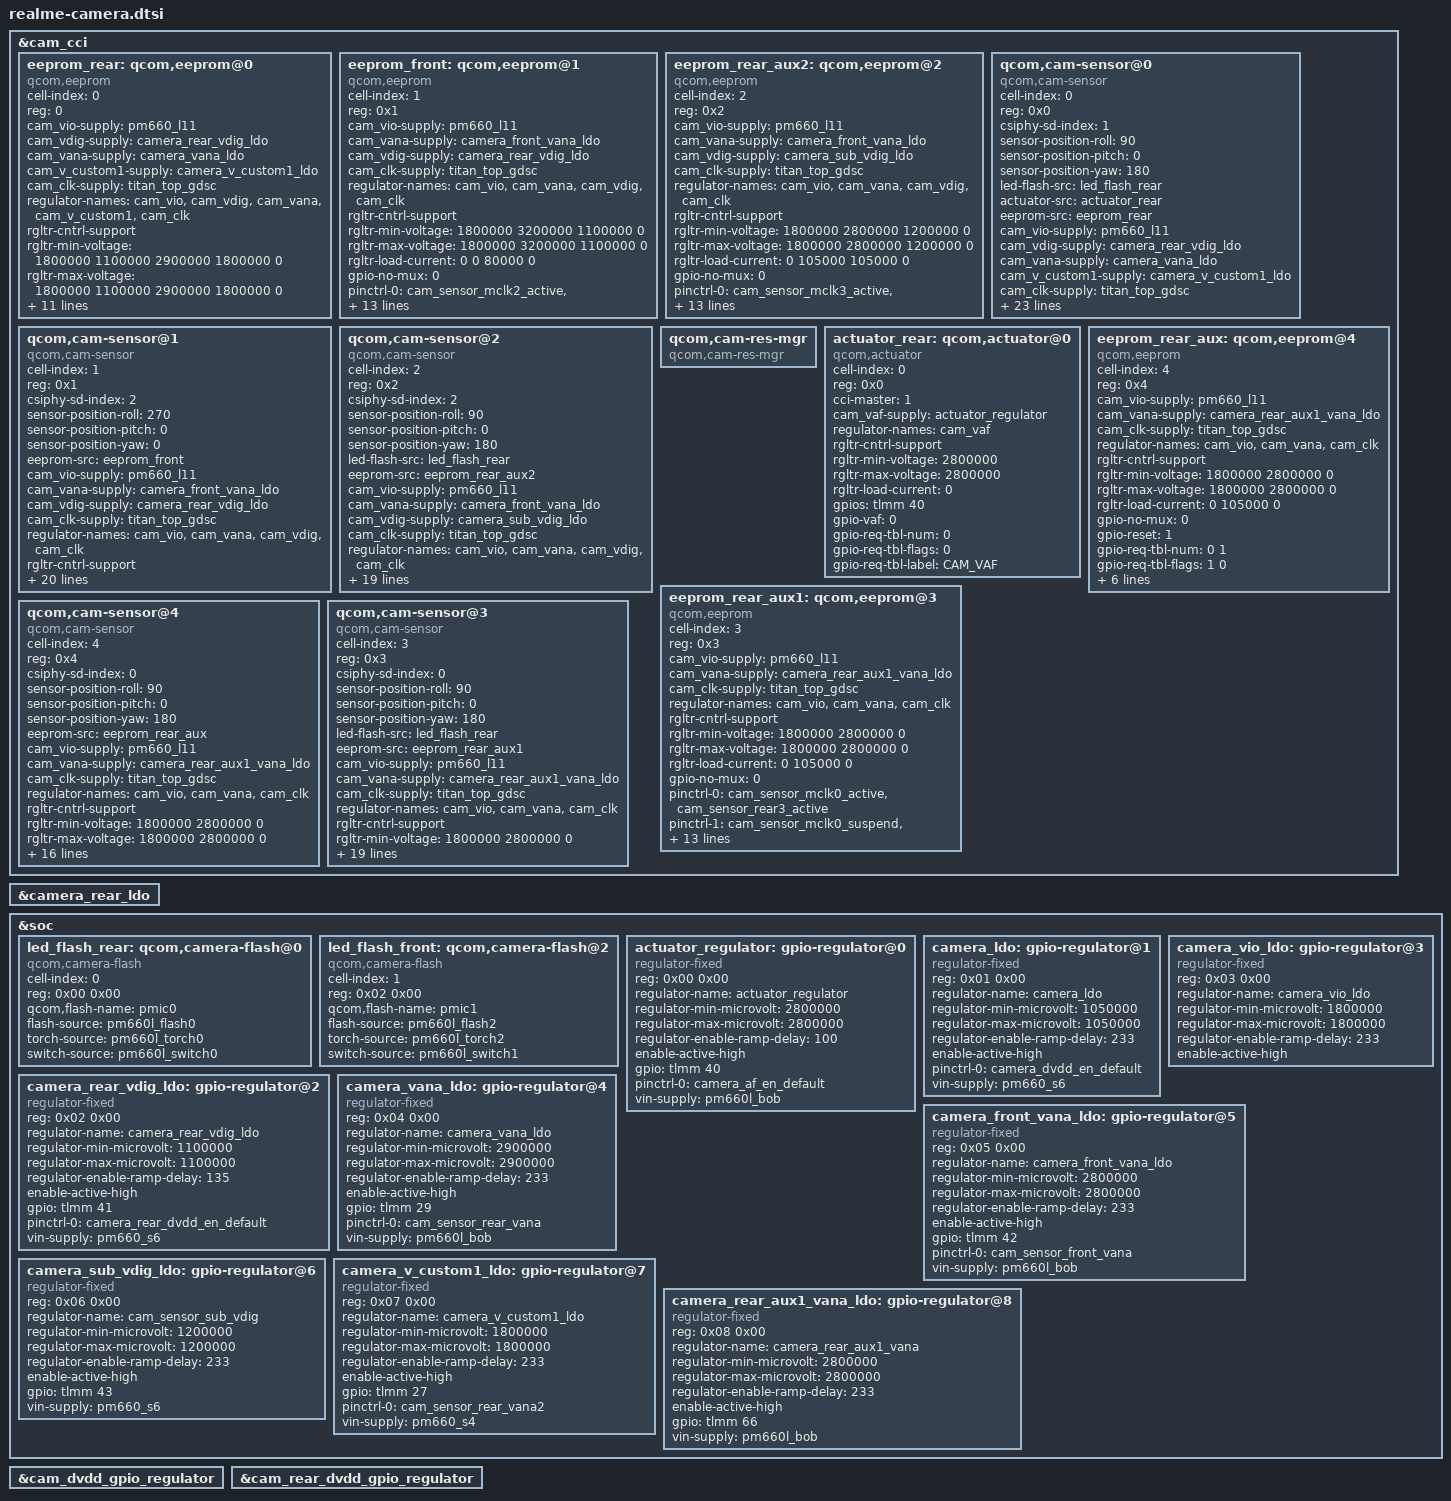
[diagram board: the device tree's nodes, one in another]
// SPDX-License-Identifier: GPL-2.0
// Copyright (c) 2021, Divyanshu-Modi <divyan.m05@gmail.com>
// Copyright (c) 2021, Dakkshesh07 <dakkshesh5@gmail.com>
// Copyright (c) 2021, The Linux Foundation. All rights reserved.

/* RMX 1921 specific changes */

&camera_vio_ldo {
	/delete-property/ gpio;
	/delete-property/ pinctrl-names;
	/delete-property/ pinctrl-0;
	/delete-property/ vin-supply;
};

&cam_cci {
	qcom,eeprom@0 {
                /delete-property/ pinctrl-names;
                /delete-property/ pinctrl-0;
                /delete-property/ pinctrl-1;
                /delete-property/ gpios;
        };

        qcom,eeprom@1 {
                /delete-property/ pinctrl-names;
                /delete-property/ pinctrl-0;
                /delete-property/ pinctrl-1;
                /delete-property/ gpios;
        };

        qcom,eeprom@2 {
                /delete-property/ pinctrl-names;
                /delete-property/ pinctrl-0;
                /delete-property/ pinctrl-1;
                /delete-property/ gpios;
        };

	qcom,cam-sensor@0 {
                /delete-property/ pinctrl-names;
                /delete-property/ pinctrl-0;
                /delete-property/ pinctrl-1;
                /delete-property/ gpios;
        };

        qcom,cam-sensor@1 {
                /delete-property/ pinctrl-names;
                /delete-property/ pinctrl-0;
                /delete-property/ pinctrl-1;
                /delete-property/ gpios;
        };

        qcom,cam-sensor@2 {
                /delete-property/ pinctrl-names;
                /delete-property/ pinctrl-0;
                /delete-property/ pinctrl-1;
                /delete-property/ gpios;
        };
};

&camera_rear_ldo {
	/delete-property/ gpio;
};

&eeprom_rear {
        /delete-property/ pinctrl-names;
        /delete-property/ pinctrl-0;
        /delete-property/ pinctrl-1;
        /delete-property/ gpios;
};

&eeprom_rear_aux {
        /delete-property/ pinctrl-names;
        /delete-property/ pinctrl-0;
        /delete-property/ pinctrl-1;
        /delete-property/ gpios;
};

&camera_ldo {
	/delete-property/ gpio;
};

&camera_rear_ldo {
        /delete-property/ gpio;
};

/delete-node/ qcom,camera-flash@0;
/delete-node/ qcom,camera-flash@1;
/delete-node/ qcom,camera-flash@2;
/delete-node/ gpio-regulator@0;
/delete-node/ gpio-regulator@2;
/delete-node/ gpio-regulator@1;
/delete-node/ gpio-regulator@3;
/delete-node/ gpio-regulator@4;
/delete-node/ qcom,cam-res-mgr;
/delete-node/ qcom,actuator@0;
/delete-node/ qcom,actuator@1;
/delete-node/ qcom,actuator@2;
/delete-node/ qcom,ois@0;
/delete-node/ qcom,eeprom@0;
/delete-node/ qcom,eeprom@1;
/delete-node/ qcom,eeprom@2;
/delete-node/ qcom,cam-sensor@0;
/delete-node/ qcom,cam-sensor@1;
/delete-node/ qcom,cam-sensor@2;
/delete-node/ qcom,cam-sensor@3;

&soc {
	led_flash_rear: qcom,camera-flash@0 {
		cell-index = <0>;
		reg = <0x00 0x00>;
		compatible = "qcom,camera-flash";
		qcom,flash-name = "pmic0";
		flash-source = <&pm660l_flash0 /*&pm660l_flash1*/>;
		torch-source = <&pm660l_torch0 /*&pm660l_torch1*/>;
		switch-source = <&pm660l_switch0>;
		status = "ok";
	};

	led_flash_front: qcom,camera-flash@2 {
		cell-index = <1>;
		reg = <0x02 0x00>;
		compatible = "qcom,camera-flash";
		qcom,flash-name = "pmic1";
		flash-source = <&pm660l_flash2>;
		torch-source = <&pm660l_torch2>;
		switch-source = <&pm660l_switch1>;
		status = "ok";
	};

	actuator_regulator: gpio-regulator@0 {
		compatible = "regulator-fixed";
		reg = <0x00 0x00>;
		regulator-name = "actuator_regulator";
		regulator-min-microvolt = <2800000>;
		regulator-max-microvolt = <2800000>;
		regulator-enable-ramp-delay = <100>;
		enable-active-high;
		gpio = <&tlmm 40 0>;
		pinctrl-names = "default";
		pinctrl-0 = <&camera_af_en_default>;
		vin-supply = <&pm660l_bob>;
	};

	camera_ldo: gpio-regulator@1 {
		compatible = "regulator-fixed";
		reg = <0x01 0x00>;
		regulator-name = "camera_ldo";
		regulator-min-microvolt = <1050000>;
		regulator-max-microvolt = <1050000>;
		regulator-enable-ramp-delay = <233>;
		enable-active-high;
		gpio = <&tlmm 134 0>;
		pinctrl-names = "default";
		pinctrl-0 = <&camera_dvdd_en_default>;
		vin-supply = <&pm660_s6>;
	};

	camera_rear_vdig_ldo: gpio-regulator@2 {
		compatible = "regulator-fixed";
		reg = <0x02 0x00>;
		regulator-name = "camera_rear_vdig_ldo";
		regulator-min-microvolt = <1100000>;
		regulator-max-microvolt = <1100000>;
		regulator-enable-ramp-delay = <135>;
		enable-active-high;
		gpio = <&tlmm 41 0>;
		pinctrl-names = "default";
		pinctrl-0 = <&camera_rear_dvdd_en_default>;
		vin-supply = <&pm660_s6>;
	};

	camera_vio_ldo: gpio-regulator@3 {
		compatible = "regulator-fixed";
		reg = <0x03 0x00>;
		regulator-name = "camera_vio_ldo";
		regulator-min-microvolt = <1800000>;
		regulator-max-microvolt = <1800000>;
		regulator-enable-ramp-delay = <233>;
		enable-active-high;
		vin-supply = <&pm660_s4>;
	};

	camera_vana_ldo: gpio-regulator@4 {
		compatible = "regulator-fixed";
		reg = <0x04 0x00>;
		regulator-name = "camera_vana_ldo";
		regulator-min-microvolt = <2900000>;
		regulator-max-microvolt = <2900000>;
		regulator-enable-ramp-delay = <233>;
		enable-active-high;
		gpio = <&tlmm 29 0>;
		pinctrl-names = "default";
		pinctrl-0 = <&cam_sensor_rear_vana>;
		vin-supply = <&pm660l_bob>;
	};

	camera_front_vana_ldo: gpio-regulator@5 {
		compatible = "regulator-fixed";
		reg = <0x05 0x00>;
		regulator-name = "camera_front_vana_ldo";
		regulator-min-microvolt = <2800000>;
		regulator-max-microvolt = <2800000>;
		regulator-enable-ramp-delay = <233>;
		enable-active-high;
		gpio = <&tlmm 42 0>;
		pinctrl-names = "default";
		pinctrl-0 = <&cam_sensor_front_vana>;
		vin-supply = <&pm660l_bob>;
	};

	camera_sub_vdig_ldo: gpio-regulator@6 {
		compatible = "regulator-fixed";
		reg = <0x06 0x00>;
		regulator-name = "cam_sensor_sub_vdig";
		regulator-min-microvolt = <1200000>;
		regulator-max-microvolt = <1200000>;
		regulator-enable-ramp-delay = <233>;
		enable-active-high;
		gpio = <&tlmm 43 0>;
		pinctrl-names = "default";
		vin-supply = <&pm660_s6>;
	};

	camera_v_custom1_ldo: gpio-regulator@7 {
		compatible = "regulator-fixed";
		reg = <0x07 0x00>;
		regulator-name = "camera_v_custom1_ldo";
		regulator-min-microvolt = <1800000>;
		regulator-max-microvolt = <1800000>;
		regulator-enable-ramp-delay = <233>;
		enable-active-high;
		gpio = <&tlmm 27 0>;
		pinctrl-names = "default";
		pinctrl-0 = <&cam_sensor_rear_vana2>;
		vin-supply = <&pm660_s4>;
	};

	camera_rear_aux1_vana_ldo: gpio-regulator@8 {
		compatible = "regulator-fixed";
		reg = <0x08 0x00>;
		regulator-name = "camera_rear_aux1_vana";
		regulator-min-microvolt = <2800000>;
		regulator-max-microvolt = <2800000>;
		regulator-enable-ramp-delay = <233>;
		enable-active-high;
		gpio = <&tlmm 66 0>;
		vin-supply = <&pm660l_bob>;
	};
};

&cam_cci {
	qcom,cam-res-mgr {
		compatible = "qcom,cam-res-mgr";
		status = "ok";
	};

	actuator_rear: qcom,actuator@0 {
		cell-index = <0>;
		reg = <0x0>;
		compatible = "qcom,actuator";
		cci-master = <1>;
		cam_vaf-supply = <&actuator_regulator>;
		regulator-names = "cam_vaf";
		rgltr-cntrl-support;
		rgltr-min-voltage = <2800000>;
		rgltr-max-voltage = <2800000>;
		rgltr-load-current = <0>;
		gpios = <&tlmm 40 0>;
		gpio-vaf = <0>;
		gpio-req-tbl-num = <0>;
		gpio-req-tbl-flags = <0>;
		gpio-req-tbl-label = "CAM_VAF";
	};

	eeprom_rear: qcom,eeprom@0 {
		cell-index = <0>;
		reg = <0>;
		compatible = "qcom,eeprom";
		cam_vio-supply = <&pm660_l11>;
		cam_vdig-supply = <&camera_rear_vdig_ldo>;
		cam_vana-supply = <&camera_vana_ldo>;
		cam_v_custom1-supply = <&camera_v_custom1_ldo>;
		cam_clk-supply = <&titan_top_gdsc>;
		regulator-names = "cam_vio", "cam_vdig", "cam_vana", "cam_v_custom1",
			"cam_clk";
		rgltr-cntrl-support;
		rgltr-min-voltage = <1800000 1100000 2900000 1800000 0>;
		rgltr-max-voltage = <1800000 1100000 2900000 1800000 0>;
		rgltr-load-current = <0 80000 105000 0 0>;
		gpio-no-mux = <0>;
		pinctrl-names = "cam_default", "cam_suspend";
		pinctrl-0 = <&cam_sensor_mclk1_active
				&cam_sensor_rear_active>;
		pinctrl-1 = <&cam_sensor_mclk1_suspend
				&cam_sensor_rear_suspend>;
		gpios = <&tlmm 14 0>,
		        <&tlmm 28 0>;
		gpio-reset = <1>;
		gpio-req-tbl-num = <0 1>;
		gpio-req-tbl-flags = <1 0>;
		gpio-req-tbl-label = "CAMIF_MCLK0",
					"CAM_RESET0";
		sensor-mode = <0>;
		cci-master = <1>;
		status = "ok";
		clocks = <&clock_camcc CAM_CC_MCLK1_CLK>;
		clock-names = "cam_clk";
		clock-cntl-level = "turbo";
		clock-rates = <24000000>;
	};

	eeprom_front: qcom,eeprom@1 {
		cell-index = <1>;
		reg = <0x1>;
		compatible = "qcom,eeprom";
		cam_vio-supply = <&pm660_l11>;
		cam_vana-supply = <&camera_front_vana_ldo>;
		cam_vdig-supply = <&camera_rear_vdig_ldo>;
		cam_clk-supply = <&titan_top_gdsc>;
		regulator-names =  "cam_vio", "cam_vana","cam_vdig",
			"cam_clk";
		rgltr-cntrl-support;
		rgltr-min-voltage = <1800000 3200000 1100000 0>;
		rgltr-max-voltage = <1800000 3200000 1100000 0>;
		rgltr-load-current = <0 0 80000 0>;
		gpio-no-mux = <0>;
		pinctrl-names = "cam_default", "cam_suspend";
		pinctrl-0 = <&cam_sensor_mclk2_active
				&cam_sensor_front_active>;
		pinctrl-1 = <&cam_sensor_mclk2_suspend
				&cam_sensor_front_suspend>;
		gpios = <&tlmm 15 0>,
			<&tlmm 9 0>;
		gpio-reset = <1>;
		gpio-req-tbl-num = <0 1>;
		gpio-req-tbl-flags = <1 0>;
		gpio-req-tbl-label = "CAMIF_MCLK1",
					"CAM_RESET1";
		sensor-mode = <0>;
		cci-master = <0>;
		status = "ok";
		clocks = <&clock_camcc CAM_CC_MCLK2_CLK>;
		clock-names = "cam_clk";
		clock-cntl-level = "turbo";
		clock-rates = <24000000>;
	};

	eeprom_rear_aux: qcom,eeprom@4 {
		cell-index = <4>;
		reg = <0x4>;
		compatible = "qcom,eeprom";
		cam_vio-supply = <&pm660_l11>;
		cam_vana-supply = <&camera_rear_aux1_vana_ldo>;
		cam_clk-supply = <&titan_top_gdsc>;
		regulator-names = "cam_vio", "cam_vana",
			"cam_clk";
		rgltr-cntrl-support;
		rgltr-min-voltage = <1800000 2800000 0>;
		rgltr-max-voltage = <1800000 2800000 0>;
		rgltr-load-current = <0 105000 0>;
		gpio-no-mux = <0>;
		pinctrl-names = "cam_default", "cam_suspend";
		pinctrl-0 = <&cam_sensor_mclk0_active
				 &cam_sensor_rear2_active>;
		pinctrl-1 = <&cam_sensor_mclk0_suspend
				 &cam_sensor_rear2_suspend>;
		gpios = <&tlmm 13 0>,
			<&tlmm 49 0>;
		gpio-reset = <1>;
		gpio-req-tbl-num = <0 1>;
		gpio-req-tbl-flags = <1 0>;
		gpio-req-tbl-label = "CAMIF_MCLK2",
					"CAM_RESET2";
		sensor-mode = <0>;
		cci-master = <0>;
		status = "ok";
		clocks = <&clock_camcc CAM_CC_MCLK0_CLK>;
		clock-names = "cam_clk";
		clock-cntl-level = "turbo";
		clock-rates = <24000000>;
	};

	eeprom_rear_aux1: qcom,eeprom@3 {
		cell-index = <3>;
		reg = <0x3>;
		compatible = "qcom,eeprom";
		cam_vio-supply = <&pm660_l11>;
		cam_vana-supply = <&camera_rear_aux1_vana_ldo>;
		cam_clk-supply = <&titan_top_gdsc>;
		regulator-names = "cam_vio", "cam_vana",
			"cam_clk";
		rgltr-cntrl-support;
		rgltr-min-voltage = <1800000 2800000 0>;
		rgltr-max-voltage = <1800000 2800000 0>;
		rgltr-load-current = <0 105000 0>;
		gpio-no-mux = <0>;
		pinctrl-names = "cam_default", "cam_suspend";
		pinctrl-0 = <&cam_sensor_mclk0_active
				 &cam_sensor_rear3_active>;
		pinctrl-1 = <&cam_sensor_mclk0_suspend
				 &cam_sensor_rear3_suspend>;
		gpios = <&tlmm 13 0>,
			<&tlmm 95 0>,
			<&tlmm 68 0>;
		gpio-reset = <1>;
		gpio-custom1 = <2>;
		gpio-req-tbl-num = <0 1 2>;
		gpio-req-tbl-flags = <1 0 0>;
		gpio-req-tbl-label = "CAMIF_MCLK3",
					"CAM_RESET3",
					"CAM_CUSTOM1";
		sensor-mode = <0>;
		cci-master = <1>;
		status = "ok";
		clocks = <&clock_camcc CAM_CC_MCLK0_CLK>;
		clock-names = "cam_clk";
		clock-cntl-level = "turbo";
		clock-rates = <24000000>;
	};

	eeprom_rear_aux2: qcom,eeprom@2 {
		cell-index = <2>;
		reg = <0x2>;
		compatible = "qcom,eeprom";
		cam_vio-supply = <&pm660_l11>;
		cam_vana-supply = <&camera_front_vana_ldo>;
		cam_vdig-supply = <&camera_sub_vdig_ldo>;
		cam_clk-supply = <&titan_top_gdsc>;
		regulator-names = "cam_vio", "cam_vana", "cam_vdig",
			"cam_clk";
		rgltr-cntrl-support;
		rgltr-min-voltage = <1800000 2800000 1200000 0>;
		rgltr-max-voltage = <1800000 2800000 1200000 0>;
		rgltr-load-current = <0 105000 105000 0>;
		gpio-no-mux = <0>;
		pinctrl-names = "cam_default", "cam_suspend";
		pinctrl-0 = <&cam_sensor_mclk3_active
				 &cam_sensor_rear4_active>;
		pinctrl-1 = <&cam_sensor_mclk3_suspend
				 &cam_sensor_rear4_suspend>;
		gpios = <&tlmm 16 0>,
				<&tlmm 30 0>;
		gpio-reset = <1>;
		gpio-req-tbl-num = <0 1>;
		gpio-req-tbl-flags = <1 0>;
		gpio-req-tbl-label = "CAMIF_MCLK4",
                    "CAM_RESET4";
		sensor-mode = <0>;
		cci-master = <0>;
		status = "ok";
		clocks = <&clock_camcc CAM_CC_MCLK3_CLK>;
		clock-names = "cam_clk";
		clock-cntl-level = "turbo";
		clock-rates = <24000000>;
	};

	qcom,cam-sensor@0 {
		cell-index = <0>;
		compatible = "qcom,cam-sensor";
		reg = <0x0>;
		csiphy-sd-index = <1>;
		sensor-position-roll = <90>;
		sensor-position-pitch = <0>;
		sensor-position-yaw = <180>;
		led-flash-src = <&led_flash_rear>;
		actuator-src = <&actuator_rear>;
		/*ois-src = <&ois_rear>;*/
		eeprom-src = <&eeprom_rear>;
		cam_vio-supply = <&pm660_l11>;
		cam_vdig-supply = <&camera_rear_vdig_ldo>;
		cam_vana-supply = <&camera_vana_ldo>;
		cam_v_custom1-supply = <&camera_v_custom1_ldo>;
		cam_clk-supply = <&titan_top_gdsc>;
		regulator-names = "cam_vio", "cam_vdig", "cam_vana", "cam_v_custom1",
			"cam_clk";
		rgltr-cntrl-support;
		rgltr-min-voltage = <1800000 1100000 2900000 1800000 0>;
		rgltr-max-voltage = <1800000 1100000 2900000 1800000 0>;
		rgltr-load-current = <0 80000 105000 0 0>;
		gpio-no-mux = <0>;
		pinctrl-names = "cam_default", "cam_suspend";
		pinctrl-0 = <&cam_sensor_mclk1_active
				&cam_sensor_rear_active>;
		pinctrl-1 = <&cam_sensor_mclk1_suspend
				&cam_sensor_rear_suspend>;
		gpios = <&tlmm 14 0>,
		        <&tlmm 28 0>;
		gpio-reset = <1>;
		gpio-req-tbl-num = <0 1>;
		gpio-req-tbl-flags = <1 0>;
		gpio-req-tbl-label = "CAMIF_MCLK0",
					"CAM_RESET0";
		sensor-mode = <0>;
		cci-master = <1>;
		status = "ok";
		clocks = <&clock_camcc CAM_CC_MCLK1_CLK>;
		clock-names = "cam_clk";
		clock-cntl-level = "turbo";
		clock-rates = <24000000>;
	};

	qcom,cam-sensor@1 {
		cell-index = <1>;
		compatible = "qcom,cam-sensor";
		reg = <0x1>;
		csiphy-sd-index = <2>;
		sensor-position-roll = <270>;
		sensor-position-pitch = <0>;
		sensor-position-yaw = <0>;
		/*led-flash-src = <&led_flash_front>;*/
		/*actuator-src = <&actuator_rear_aux>;*/
		eeprom-src = <&eeprom_front>;
		cam_vio-supply = <&pm660_l11>;
		cam_vana-supply = <&camera_front_vana_ldo>;
		cam_vdig-supply = <&camera_rear_vdig_ldo>;
		cam_clk-supply = <&titan_top_gdsc>;
		regulator-names =  "cam_vio", "cam_vana","cam_vdig",
			"cam_clk";
		rgltr-cntrl-support;
		rgltr-min-voltage = <1800000 2800000 1100000 0>;
		rgltr-max-voltage = <1800000 2800000 1100000 0>;
		rgltr-load-current = <0 105000 80000 0>;
		gpio-no-mux = <0>;
		pinctrl-names = "cam_default", "cam_suspend";
		pinctrl-0 = <&cam_sensor_mclk2_active
				&cam_sensor_front_active>;
		pinctrl-1 = <&cam_sensor_mclk2_suspend
				&cam_sensor_front_suspend>;
		gpios = <&tlmm 15 0>,
			<&tlmm 9 0>,
			<&tlmm 50 0>;
		gpio-reset = <1>;
		gpio-custom1 = <2>;
		gpio-req-tbl-num = <0 1 2>;
		gpio-req-tbl-flags = <1 0 0>;
		gpio-req-tbl-label = "CAMIF_MCLK1",
					"CAM_RESET1",
					"CAM_CUSTOM1";
		sensor-mode = <0>;
		cci-master = <0>;
		status = "ok";
		clocks = <&clock_camcc CAM_CC_MCLK2_CLK>;
		clock-names = "cam_clk";
		clock-cntl-level = "turbo";
		clock-rates = <24000000>;
	};

	qcom,cam-sensor@4 {
		cell-index = <4>;
		compatible = "qcom,cam-sensor";
		reg = <0x4>;
		csiphy-sd-index = <0>;
		sensor-position-roll = <90>;
		sensor-position-pitch = <0>;
		sensor-position-yaw = <180>;
		eeprom-src = <&eeprom_rear_aux>;
		cam_vio-supply = <&pm660_l11>;
		cam_vana-supply = <&camera_rear_aux1_vana_ldo>;
		cam_clk-supply = <&titan_top_gdsc>;
		regulator-names = "cam_vio", "cam_vana",
			"cam_clk";
		rgltr-cntrl-support;
		rgltr-min-voltage = <1800000 2800000 0>;
		rgltr-max-voltage = <1800000 2800000 0>;
		rgltr-load-current = <0 105000 0>;
		gpio-no-mux = <0>;
		pinctrl-names = "cam_default", "cam_suspend";
		pinctrl-0 = <&cam_sensor_mclk0_active
				 &cam_sensor_rear2_active>;
		pinctrl-1 = <&cam_sensor_mclk0_suspend
				 &cam_sensor_rear2_suspend>;
		gpios = <&tlmm 13 0>,
			<&tlmm 49 0>;
		gpio-reset = <1>;
		gpio-req-tbl-num = <0 1>;
		gpio-req-tbl-flags = <1 0>;
		gpio-req-tbl-label = "CAMIF_MCLK2",
					"CAM_RESET2";
		sensor-mode = <0>;
		cci-master = <0>;
		status = "ok";
		clocks = <&clock_camcc CAM_CC_MCLK0_CLK>;
		clock-names = "cam_clk";
		clock-cntl-level = "turbo";
		clock-rates = <24000000>;
	};

	qcom,cam-sensor@3 {
		cell-index = <3>;
		compatible = "qcom,cam-sensor";
		reg = <0x3>;
		csiphy-sd-index = <0>;
		sensor-position-roll = <90>;
		sensor-position-pitch = <0>;
		sensor-position-yaw = <180>;
		led-flash-src = <&led_flash_rear>;
		eeprom-src = <&eeprom_rear_aux1>;
		cam_vio-supply = <&pm660_l11>;
		cam_vana-supply = <&camera_rear_aux1_vana_ldo>;
		cam_clk-supply = <&titan_top_gdsc>;
		regulator-names = "cam_vio", "cam_vana",
			"cam_clk";
		rgltr-cntrl-support;
		rgltr-min-voltage = <1800000 2800000 0>;
		rgltr-max-voltage = <1800000 2800000 0>;
		rgltr-load-current = <0 105000 0>;
		gpio-no-mux = <0>;
		pinctrl-names = "cam_default", "cam_suspend";
		pinctrl-0 = <&cam_sensor_mclk0_active
				 &cam_sensor_rear3_active>;
		pinctrl-1 = <&cam_sensor_mclk0_suspend
				 &cam_sensor_rear3_suspend>;
		gpios = <&tlmm 13 0>,
			<&tlmm 95 0>,
			<&tlmm 68 0>;
		gpio-reset = <1>;
		gpio-custom1 = <2>;
		gpio-req-tbl-num = <0 1 2>;
		gpio-req-tbl-flags = <1 0 0>;
		gpio-req-tbl-label = "CAMIF_MCLK3",
                    "CAM_RESET3",
					"CAM_CUSTOM1";
		sensor-mode = <0>;
		cci-master = <1>;
		status = "ok";
		clocks = <&clock_camcc CAM_CC_MCLK0_CLK>;
		clock-names = "cam_clk";
		clock-cntl-level = "turbo";
		clock-rates = <24000000>;
	};

	qcom,cam-sensor@2 {
		cell-index = <2>;
		compatible = "qcom,cam-sensor";
		reg = <0x2>;
		csiphy-sd-index = <2>;
		sensor-position-roll = <90>;
		sensor-position-pitch = <0>;
		sensor-position-yaw = <180>;
		led-flash-src = <&led_flash_rear>;
		eeprom-src = <&eeprom_rear_aux2>;
		cam_vio-supply = <&pm660_l11>;
		cam_vana-supply = <&camera_front_vana_ldo>;
		cam_vdig-supply = <&camera_sub_vdig_ldo>;
		cam_clk-supply = <&titan_top_gdsc>;
		regulator-names = "cam_vio", "cam_vana", "cam_vdig",
			"cam_clk";
		rgltr-cntrl-support;
		rgltr-min-voltage = <1800000 2800000 1200000 0>;
		rgltr-max-voltage = <1800000 2800000 1200000 0>;
		rgltr-load-current = <0 105000 105000 0>;
		gpio-no-mux = <0>;
		pinctrl-names = "cam_default", "cam_suspend";
		pinctrl-0 = <&cam_sensor_mclk3_active
				 &cam_sensor_rear4_active>;
		pinctrl-1 = <&cam_sensor_mclk3_suspend
				 &cam_sensor_rear4_suspend>;
		gpios = <&tlmm 16 0>,
			<&tlmm 30 0>;
		gpio-reset = <1>;
		gpio-req-tbl-num = <0 1>;
		gpio-req-tbl-flags = <1 0>;
		gpio-req-tbl-label = "CAMIF_MCLK4",
                    "CAM_RESET4";
		sensor-mode = <0>;
		cci-master = <0>;
		status = "ok";
		clocks = <&clock_camcc CAM_CC_MCLK3_CLK>;
		clock-names = "cam_clk";
		clock-cntl-level = "turbo";
		clock-rates = <24000000>;
	};
};

&cam_dvdd_gpio_regulator {
	/delete-property/ gpio;
};

&cam_rear_dvdd_gpio_regulator {
        /delete-property/ gpio;
};

/delete-node/ cam_sensor_rear_active;
/delete-node/ cam_sensor_rear_suspend;
/delete-node/ cam_sensor_front_active;
/delete-node/ cam_sensor_front_suspend;
